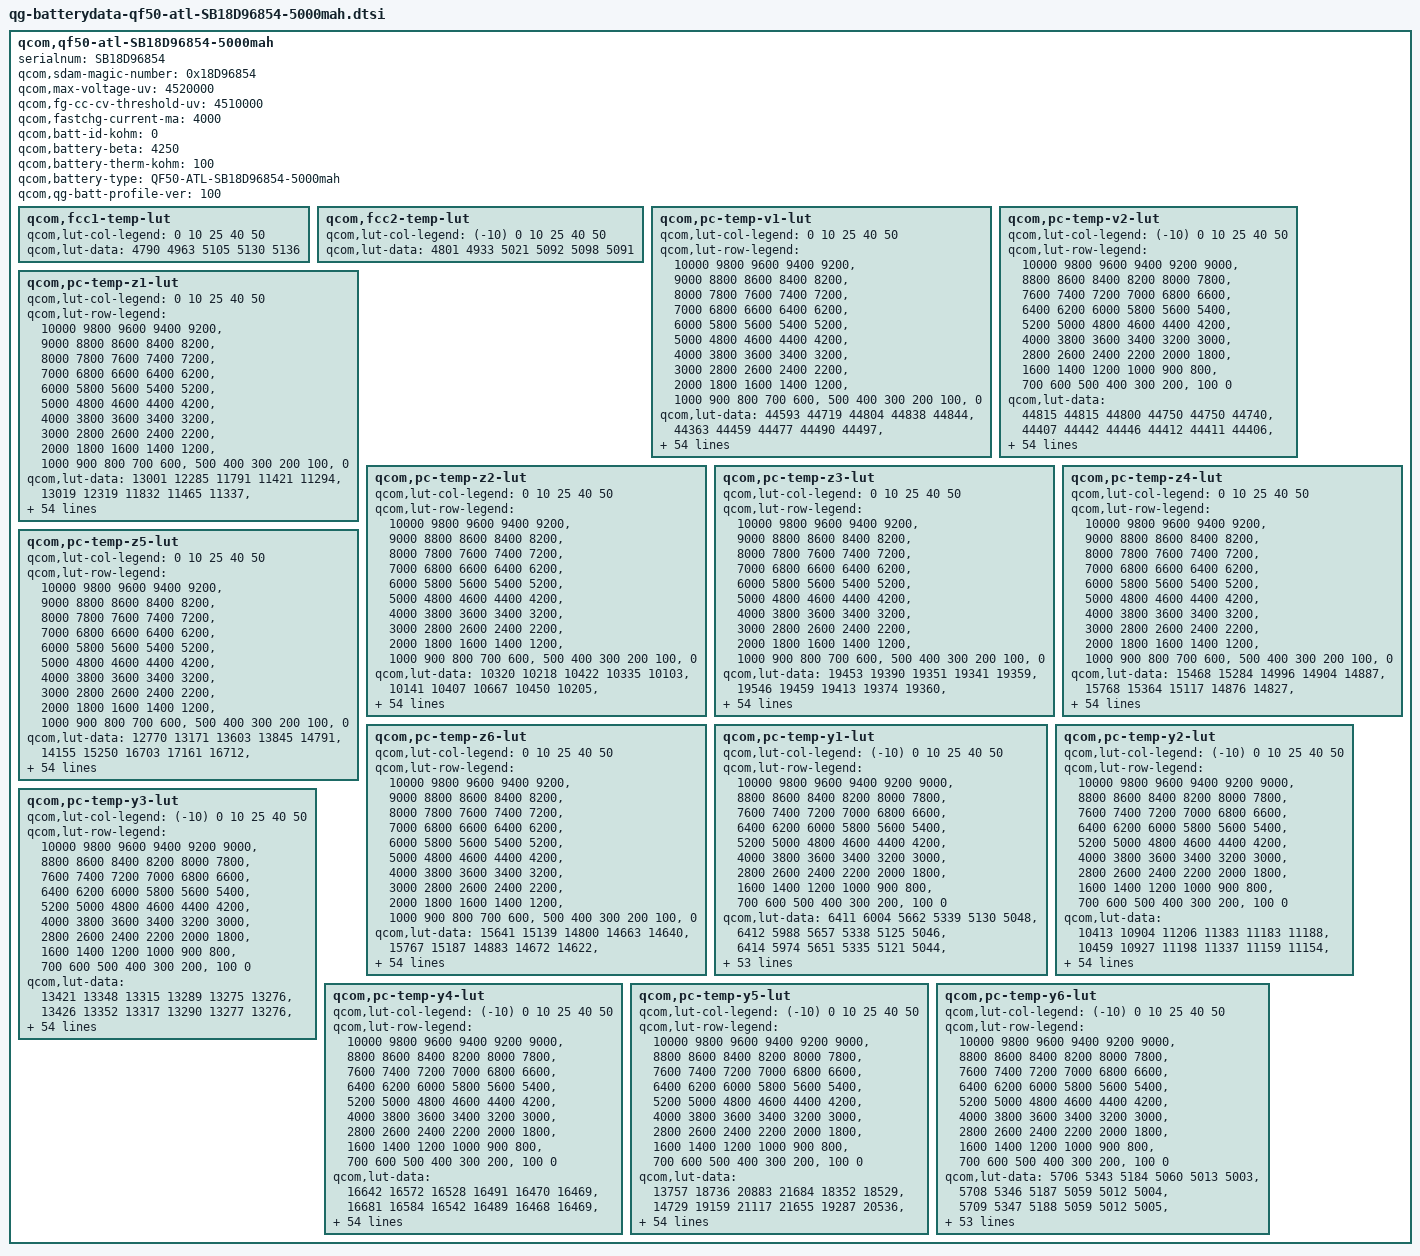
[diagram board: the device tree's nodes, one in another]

qcom,qf50-atl-SB18D96854-5000mah {
    /* ATL_SB18D96854_5000mAH_averaged_MasterSlave_Oct9th2023 */
    serialnum = "SB18D96854";
    qcom,sdam-magic-number = <0x18D96854>;
    qcom,max-voltage-uv = <4520000>;
    qcom,fg-cc-cv-threshold-uv = <4510000>;
    qcom,fastchg-current-ma = <4000>;
    qcom,batt-id-kohm = <0>;
    qcom,battery-beta = <4250>;
    qcom,battery-therm-kohm = <100>;
    qcom,battery-type = "QF50-ATL-SB18D96854-5000mah";
    qcom,qg-batt-profile-ver = <100>;

	qcom,fcc1-temp-lut {
		qcom,lut-col-legend = <0 10 25 40 50>;
		qcom,lut-data = <4790 4963 5105 5130 5136>;
	};

	qcom,fcc2-temp-lut {
		qcom,lut-col-legend = <(-10) 0 10 25 40 50>;
		qcom,lut-data = <4801 4933 5021 5092 5098 5091>;
	};

	qcom,pc-temp-v1-lut {
		qcom,lut-col-legend = <0 10 25 40 50>;
		qcom,lut-row-legend = <10000 9800 9600 9400 9200>,
			<9000 8800 8600 8400 8200>,
			<8000 7800 7600 7400 7200>,
			<7000 6800 6600 6400 6200>,
			<6000 5800 5600 5400 5200>,
			<5000 4800 4600 4400 4200>,
			<4000 3800 3600 3400 3200>,
			<3000 2800 2600 2400 2200>,
			<2000 1800 1600 1400 1200>,
			<1000 900 800 700 600>,
			<500 400 300 200 100>,
			<0>;
		qcom,lut-data = <44593 44719 44804 44838 44844>,
			<44363 44459 44477 44490 44497>,
			<44144 44230 44243 44243 44244>,
			<43927 44019 44035 44031 44030>,
			<43713 43810 43820 43818 43818>,
			<43498 43596 43604 43604 43606>,
			<43273 43372 43381 43385 43390>,
			<43035 43137 43142 43153 43158>,
			<42792 42894 42895 42911 42914>,
			<42551 42644 42646 42663 42666>,
			<42310 42393 42393 42408 42414>,
			<42073 42146 42141 42154 42162>,
			<41839 41903 41889 41903 41914>,
			<41609 41666 41642 41656 41669>,
			<41387 41435 41405 41418 41431>,
			<41171 41209 41175 41184 41198>,
			<40963 40990 40953 40960 40972>,
			<40761 40781 40738 40744 40753>,
			<40565 40581 40532 40539 40543>,
			<40376 40391 40342 40345 40348>,
			<40196 40208 40161 40165 40169>,
			<40017 40026 39958 39961 39968>,
			<39832 39829 39722 39704 39713>,
			<39642 39584 39487 39452 39461>,
			<39449 39308 39263 39253 39271>,
			<39236 39091 39056 39084 39112>,
			<39033 38952 38915 38947 38967>,
			<38893 38848 38817 38837 38830>,
			<38793 38757 38729 38737 38709>,
			<38708 38674 38639 38633 38609>,
			<38631 38593 38555 38534 38521>,
			<38562 38516 38475 38446 38438>,
			<38499 38443 38399 38368 38361>,
			<38440 38377 38330 38296 38287>,
			<38385 38316 38270 38227 38216>,
			<38335 38263 38215 38161 38145>,
			<38289 38219 38159 38095 38074>,
			<38243 38179 38104 38031 37999>,
			<38199 38129 38036 37954 37912>,
			<38151 38063 37943 37851 37796>,
			<38082 37978 37834 37733 37667>,
			<37977 37865 37713 37614 37543>,
			<37855 37731 37574 37487 37414>,
			<37710 37574 37403 37324 37244>,
			<37573 37406 37240 37171 37097>,
			<37402 37260 37123 37076 37019>,
			<37316 37197 37089 37042 36986>,
			<37241 37152 37063 37019 36962>,
			<37178 37120 37041 36998 36938>,
			<37126 37083 36997 36945 36882>,
			<37082 36997 36796 36700 36622>,
			<37038 36781 36363 36256 36180>,
			<36969 36458 35772 35667 35597>,
			<36769 35910 34953 34863 34801>,
			<36046 34963 33679 33606 33568>,
			<30000 30000 30000 30000 30000>;
	};

	qcom,pc-temp-v2-lut {
		qcom,lut-col-legend = <(-10) 0 10 25 40 50>;
		qcom,lut-row-legend = <10000 9800 9600 9400 9200 9000>,
			<8800 8600 8400 8200 8000 7800>,
			<7600 7400 7200 7000 6800 6600>,
			<6400 6200 6000 5800 5600 5400>,
			<5200 5000 4800 4600 4400 4200>,
			<4000 3800 3600 3400 3200 3000>,
			<2800 2600 2400 2200 2000 1800>,
			<1600 1400 1200 1000 900 800>,
			<700 600 500 400 300 200>,
			<100 0>;
		qcom,lut-data = <44815 44815 44800 44750 44750 44740>,
			<44407 44442 44446 44412 44411 44406>,
			<44058 44120 44138 44113 44111 44108>,
			<43782 43862 43887 43862 43858 43856>,
			<43570 43658 43684 43653 43646 43644>,
			<43370 43460 43482 43441 43432 43430>,
			<43150 43241 43259 43211 43203 43201>,
			<42924 43016 43028 42975 42968 42965>,
			<42694 42783 42789 42731 42725 42723>,
			<42460 42540 42539 42479 42474 42472>,
			<42225 42294 42288 42227 42223 42221>,
			<41992 42052 42042 41975 41972 41972>,
			<41761 41809 41797 41725 41722 41724>,
			<41530 41572 41555 41481 41480 41482>,
			<41301 41339 41316 41244 41245 41246>,
			<41073 41112 41084 41013 41016 41017>,
			<40839 40897 40859 40787 40791 40794>,
			<40599 40690 40642 40570 40575 40580>,
			<40356 40467 40440 40366 40372 40374>,
			<40111 40218 40252 40169 40175 40175>,
			<39864 39963 40042 39964 39983 39983>,
			<39631 39715 39777 39750 39796 39802>,
			<39413 39470 39500 39529 39597 39609>,
			<39208 39248 39262 39284 39341 39357>,
			<39016 39051 39053 39038 39072 39086>,
			<38835 38873 38871 38855 38882 38895>,
			<38669 38714 38718 38714 38743 38756>,
			<38518 38570 38583 38591 38623 38636>,
			<38381 38439 38460 38476 38512 38521>,
			<38272 38314 38347 38370 38411 38417>,
			<38185 38202 38244 38274 38318 38322>,
			<38109 38107 38149 38184 38232 38237>,
			<38038 38025 38060 38103 38153 38157>,
			<37972 37952 37977 38031 38083 38085>,
			<37909 37890 37898 37962 38015 38011>,
			<37847 37833 37832 37890 37930 37918>,
			<37785 37779 37777 37816 37833 37806>,
			<37721 37730 37725 37735 37733 37694>,
			<37655 37673 37667 37646 37630 37587>,
			<37584 37596 37598 37551 37525 37480>,
			<37506 37504 37511 37454 37428 37384>,
			<37421 37406 37402 37350 37328 37287>,
			<37330 37300 37266 37220 37200 37161>,
			<37233 37174 37106 37072 37060 37018>,
			<37130 37022 36934 36927 36933 36885>,
			<37023 36864 36784 36857 36879 36834>,
			<36972 36796 36726 36836 36868 36823>,
			<36922 36732 36672 36813 36853 36809>,
			<36865 36674 36610 36782 36827 36779>,
			<36798 36606 36517 36704 36751 36698>,
			<36719 36495 36306 36440 36464 36398>,
			<36622 36353 35951 35932 35962 35898>,
			<36513 36035 35540 35247 35298 35239>,
			<36210 35567 34813 34264 34365 34314>,
			<36001 35211 33926 32680 32928 32922>,
			<35909 34566 32099 29510 28715 29333>;
	};

	qcom,pc-temp-z1-lut {
		qcom,lut-col-legend = <0 10 25 40 50>;
		qcom,lut-row-legend = <10000 9800 9600 9400 9200>,
			<9000 8800 8600 8400 8200>,
			<8000 7800 7600 7400 7200>,
			<7000 6800 6600 6400 6200>,
			<6000 5800 5600 5400 5200>,
			<5000 4800 4600 4400 4200>,
			<4000 3800 3600 3400 3200>,
			<3000 2800 2600 2400 2200>,
			<2000 1800 1600 1400 1200>,
			<1000 900 800 700 600>,
			<500 400 300 200 100>,
			<0>;
		qcom,lut-data = <13001 12285 11791 11421 11294>,
			<13019 12319 11832 11465 11337>,
			<13012 12323 11823 11455 11331>,
			<13004 12312 11815 11449 11328>,
			<12989 12300 11804 11444 11325>,
			<12968 12290 11789 11438 11322>,
			<12954 12280 11775 11433 11319>,
			<12945 12265 11764 11427 11318>,
			<12938 12252 11753 11422 11316>,
			<12923 12239 11743 11419 11316>,
			<12886 12220 11733 11416 11315>,
			<12862 12197 11729 11415 11315>,
			<12835 12182 11729 11413 11314>,
			<12804 12175 11729 11411 11314>,
			<12788 12173 11728 11410 11313>,
			<12765 12171 11726 11411 11313>,
			<12751 12169 11724 11412 11313>,
			<12743 12166 11724 11412 11314>,
			<12730 12165 11723 11412 11316>,
			<12725 12164 11726 11413 11317>,
			<12725 12165 11731 11415 11318>,
			<12726 12172 11733 11416 11319>,
			<12727 12180 11736 11416 11319>,
			<12729 12183 11739 11417 11320>,
			<12733 12184 11742 11418 11321>,
			<12747 12186 11746 11421 11323>,
			<12765 12194 11751 11424 11325>,
			<12776 12207 11756 11429 11328>,
			<12783 12217 11761 11434 11331>,
			<12788 12225 11766 11437 11335>,
			<12792 12233 11771 11440 11338>,
			<12800 12240 11776 11444 11342>,
			<12807 12245 11782 11450 11346>,
			<12815 12245 11788 11455 11351>,
			<12823 12245 11794 11461 11354>,
			<12826 12247 11800 11467 11358>,
			<12825 12257 11808 11473 11362>,
			<12826 12269 11818 11478 11366>,
			<12837 12282 11829 11484 11371>,
			<12854 12304 11840 11490 11376>,
			<12872 12323 11850 11496 11381>,
			<12902 12333 11857 11503 11385>,
			<12916 12343 11863 11511 11389>,
			<12918 12366 11868 11517 11393>,
			<12935 12374 11882 11524 11398>,
			<12975 12375 11894 11529 11400>,
			<12971 12399 11900 11530 11400>,
			<12977 12377 11893 11530 11400>,
			<12956 12386 11897 11534 11404>,
			<12966 12372 11909 11537 11408>,
			<12970 12406 11912 11543 11411>,
			<12977 12402 11928 11550 11416>,
			<12964 12411 11935 11558 11424>,
			<12996 12424 11950 11570 11433>,
			<12996 12424 11950 11570 11433>,
			<12996 12424 11950 11570 11433>;
	};

	qcom,pc-temp-z2-lut {
		qcom,lut-col-legend = <0 10 25 40 50>;
		qcom,lut-row-legend = <10000 9800 9600 9400 9200>,
			<9000 8800 8600 8400 8200>,
			<8000 7800 7600 7400 7200>,
			<7000 6800 6600 6400 6200>,
			<6000 5800 5600 5400 5200>,
			<5000 4800 4600 4400 4200>,
			<4000 3800 3600 3400 3200>,
			<3000 2800 2600 2400 2200>,
			<2000 1800 1600 1400 1200>,
			<1000 900 800 700 600>,
			<500 400 300 200 100>,
			<0>;
		qcom,lut-data = <10320 10218 10422 10335 10103>,
			<10141 10407 10667 10450 10205>,
			<10292 10511 10675 10590 10322>,
			<10394 10562 10674 10605 10473>,
			<10383 10566 10664 10605 10528>,
			<10358 10535 10606 10557 10481>,
			<10340 10493 10544 10487 10415>,
			<10324 10459 10501 10412 10374>,
			<10310 10435 10463 10334 10340>,
			<10296 10417 10430 10317 10333>,
			<10281 10404 10399 10332 10338>,
			<10275 10400 10387 10344 10344>,
			<10276 10402 10400 10345 10332>,
			<10278 10409 10418 10346 10308>,
			<10281 10416 10425 10351 10289>,
			<10289 10425 10429 10366 10231>,
			<10300 10438 10435 10375 10192>,
			<10316 10454 10444 10330 10198>,
			<10338 10466 10454 10270 10210>,
			<10353 10474 10459 10268 10226>,
			<10364 10480 10463 10293 10255>,
			<10373 10486 10479 10340 10307>,
			<10381 10492 10570 10536 10519>,
			<10389 10513 10643 10715 10722>,
			<10399 10541 10589 10626 10658>,
			<10418 10548 10482 10388 10456>,
			<10438 10534 10455 10315 10437>,
			<10441 10521 10461 10337 10997>,
			<10434 10520 10471 10377 11471>,
			<10428 10522 10496 10506 11283>,
			<10430 10522 10529 10697 10847>,
			<10434 10521 10549 10723 10572>,
			<10438 10523 10564 10621 10384>,
			<10443 10530 10569 10506 10275>,
			<10448 10543 10561 10398 10227>,
			<10450 10550 10549 10310 10199>,
			<10451 10548 10547 10307 10209>,
			<10452 10542 10550 10339 10269>,
			<10454 10541 10555 10383 10335>,
			<10457 10549 10576 10475 10411>,
			<10460 10555 10601 10563 10475>,
			<10464 10550 10614 10570 10489>,
			<10468 10546 10625 10546 10489>,
			<10476 10543 10676 10539 10505>,
			<10258 10612 10693 10539 10500>,
			<10202 10680 10648 10509 10438>,
			<10111 10660 10634 10502 10437>,
			<10074 10647 10596 10512 10438>,
			<10038 10892 10565 10516 10442>,
			<9961 10981 10559 10578 10553>,
			<9920 10890 10626 10515 10467>,
			<9778 10816 10640 10340 10196>,
			<9713 10647 10580 10264 10119>,
			<9769 10508 10477 10193 10026>,
			<9769 10508 10477 10193 10026>,
			<9769 10508 10477 10193 10026>;
	};

	qcom,pc-temp-z3-lut {
		qcom,lut-col-legend = <0 10 25 40 50>;
		qcom,lut-row-legend = <10000 9800 9600 9400 9200>,
			<9000 8800 8600 8400 8200>,
			<8000 7800 7600 7400 7200>,
			<7000 6800 6600 6400 6200>,
			<6000 5800 5600 5400 5200>,
			<5000 4800 4600 4400 4200>,
			<4000 3800 3600 3400 3200>,
			<3000 2800 2600 2400 2200>,
			<2000 1800 1600 1400 1200>,
			<1000 900 800 700 600>,
			<500 400 300 200 100>,
			<0>;
		qcom,lut-data = <19453 19390 19351 19341 19359>,
			<19546 19459 19413 19374 19360>,
			<19608 19497 19429 19394 19385>,
			<19641 19516 19438 19401 19392>,
			<19650 19523 19443 19405 19395>,
			<19655 19526 19446 19409 19397>,
			<19658 19527 19449 19410 19399>,
			<19661 19526 19452 19411 19402>,
			<19662 19525 19454 19411 19406>,
			<19660 19524 19452 19411 19407>,
			<19654 19522 19444 19408 19403>,
			<19648 19518 19436 19404 19398>,
			<19643 19511 19433 19401 19393>,
			<19639 19503 19430 19397 19389>,
			<19633 19496 19424 19392 19384>,
			<19627 19492 19418 19387 19379>,
			<19621 19490 19413 19382 19374>,
			<19615 19489 19410 19377 19371>,
			<19608 19487 19408 19372 19367>,
			<19603 19484 19405 19367 19361>,
			<19598 19481 19401 19362 19354>,
			<19595 19479 19401 19361 19351>,
			<19596 19480 19412 19366 19355>,
			<19600 19488 19420 19373 19359>,
			<19605 19500 19415 19365 19351>,
			<19612 19504 19405 19345 19331>,
			<19618 19500 19399 19339 19329>,
			<19619 19494 19394 19339 19382>,
			<19615 19490 19392 19340 19427>,
			<19610 19487 19394 19355 19423>,
			<19606 19486 19396 19380 19410>,
			<19603 19487 19401 19387 19398>,
			<19600 19488 19409 19385 19388>,
			<19597 19489 19413 19382 19378>,
			<19594 19489 19412 19377 19367>,
			<19592 19489 19409 19369 19357>,
			<19591 19487 19407 19362 19348>,
			<19589 19484 19403 19354 19340>,
			<19586 19480 19400 19351 19337>,
			<19582 19477 19398 19352 19337>,
			<19577 19473 19396 19353 19338>,
			<19568 19468 19393 19352 19339>,
			<19559 19464 19388 19350 19344>,
			<19552 19461 19385 19351 19350>,
			<19343 19446 19379 19351 19352>,
			<19300 19427 19373 19340 19340>,
			<19299 19429 19370 19336 19336>,
			<19296 19423 19367 19332 19326>,
			<19297 19365 19359 19327 19321>,
			<19294 19359 19355 19322 19311>,
			<19292 19358 19350 19338 19329>,
			<19273 19320 19359 19359 19350>,
			<19275 19311 19353 19364 19351>,
			<19306 19391 19382 19359 19347>,
			<19306 19391 19382 19359 19347>,
			<19306 19391 19382 19359 19347>;
	};

	qcom,pc-temp-z4-lut {
		qcom,lut-col-legend = <0 10 25 40 50>;
		qcom,lut-row-legend = <10000 9800 9600 9400 9200>,
			<9000 8800 8600 8400 8200>,
			<8000 7800 7600 7400 7200>,
			<7000 6800 6600 6400 6200>,
			<6000 5800 5600 5400 5200>,
			<5000 4800 4600 4400 4200>,
			<4000 3800 3600 3400 3200>,
			<3000 2800 2600 2400 2200>,
			<2000 1800 1600 1400 1200>,
			<1000 900 800 700 600>,
			<500 400 300 200 100>,
			<0>;
		qcom,lut-data = <15468 15284 14996 14904 14887>,
			<15768 15364 15117 14876 14827>,
			<15625 15301 15092 14911 14870>,
			<15464 15176 15003 14874 14843>,
			<15334 15064 14942 14841 14818>,
			<15210 14985 14897 14816 14798>,
			<15114 14924 14858 14793 14779>,
			<15040 14876 14823 14773 14761>,
			<14980 14837 14792 14756 14743>,
			<14933 14805 14767 14741 14732>,
			<14894 14779 14746 14728 14725>,
			<14861 14758 14731 14719 14720>,
			<14833 14741 14721 14712 14716>,
			<14810 14730 14713 14707 14714>,
			<14790 14724 14707 14702 14710>,
			<14773 14719 14703 14697 14706>,
			<14760 14714 14698 14692 14703>,
			<14750 14710 14694 14688 14699>,
			<14742 14706 14690 14684 14696>,
			<14738 14703 14685 14679 14690>,
			<14736 14700 14681 14673 14683>,
			<14735 14699 14682 14672 14681>,
			<14736 14702 14703 14706 14715>,
			<14741 14726 14734 14754 14763>,
			<14749 14776 14778 14791 14795>,
			<14776 14807 14826 14824 14821>,
			<14809 14809 14834 14831 14822>,
			<14815 14801 14821 14819 14754>,
			<14811 14789 14804 14799 14695>,
			<14806 14773 14788 14769 14691>,
			<14800 14761 14770 14731 14689>,
			<14792 14751 14754 14709 14687>,
			<14785 14742 14737 14697 14683>,
			<14779 14738 14724 14688 14679>,
			<14774 14735 14714 14683 14675>,
			<14769 14733 14708 14679 14671>,
			<14764 14730 14704 14677 14669>,
			<14758 14727 14702 14675 14668>,
			<14747 14721 14701 14675 14668>,
			<14733 14714 14703 14684 14681>,
			<14722 14706 14705 14694 14697>,
			<14714 14698 14702 14692 14693>,
			<14702 14688 14694 14686 14682>,
			<14685 14674 14688 14687 14686>,
			<14845 14654 14674 14681 14682>,
			<14881 14650 14656 14663 14658>,
			<14886 14648 14651 14661 14655>,
			<14889 14651 14641 14649 14650>,
			<14890 14712 14636 14633 14632>,
			<14892 14711 14633 14625 14623>,
			<14896 14712 14653 14644 14652>,
			<14913 14758 14660 14646 14659>,
			<14913 14772 14671 14649 14666>,
			<14897 14700 14650 14658 14676>,
			<14897 14700 14650 14658 14676>,
			<14897 14700 14650 14658 14676>;
	};

	qcom,pc-temp-z5-lut {
		qcom,lut-col-legend = <0 10 25 40 50>;
		qcom,lut-row-legend = <10000 9800 9600 9400 9200>,
			<9000 8800 8600 8400 8200>,
			<8000 7800 7600 7400 7200>,
			<7000 6800 6600 6400 6200>,
			<6000 5800 5600 5400 5200>,
			<5000 4800 4600 4400 4200>,
			<4000 3800 3600 3400 3200>,
			<3000 2800 2600 2400 2200>,
			<2000 1800 1600 1400 1200>,
			<1000 900 800 700 600>,
			<500 400 300 200 100>,
			<0>;
		qcom,lut-data = <12770 13171 13603 13845 14791>,
			<14155 15250 16703 17161 16712>,
			<15460 16798 17519 18575 19208>,
			<16507 17913 18278 19681 20781>,
			<17186 18716 18887 20445 21736>,
			<17735 19366 19336 20933 22218>,
			<18429 19987 19885 21377 22705>,
			<19387 20692 20888 21887 23950>,
			<20341 21617 22034 22444 26078>,
			<21051 22826 22766 23242 27486>,
			<21655 24169 23290 24520 28328>,
			<22383 25267 23936 25735 28849>,
			<23447 25874 25182 26603 29118>,
			<24676 26278 26306 27346 29297>,
			<25805 26748 26600 28103 29405>,
			<26879 27468 26723 29040 29718>,
			<28024 28540 26995 29658 30204>,
			<29464 29831 27992 29953 31496>,
			<31008 30970 29250 30340 33168>,
			<32018 31779 30130 30977 34135>,
			<32501 32440 30986 32230 35013>,
			<33039 33461 33285 34023 35569>,
			<34762 35326 42233 37909 36591>,
			<38685 41967 48954 41144 37496>,
			<42761 50144 43988 36443 33101>,
			<47271 51347 33537 24211 21515>,
			<51182 45323 28145 19084 18742>,
			<51272 38177 25092 17811 31918>,
			<47274 35211 23837 17285 43132>,
			<43386 33897 23940 19345 41578>,
			<41870 33680 24227 23800 37626>,
			<40821 34980 25322 26459 35269>,
			<40346 37363 28909 28337 33930>,
			<40332 39788 32294 29801 32727>,
			<40471 42627 34928 31077 31246>,
			<40676 44423 36976 32038 30007>,
			<41267 44306 37918 32266 29648>,
			<41819 43290 38596 32320 29483>,
			<42486 42860 38766 32466 29448>,
			<43208 42704 38184 33667 30081>,
			<43053 42357 37154 34906 30791>,
			<41032 40933 34830 32644 30390>,
			<39874 40008 31931 27841 29417>,
			<39457 41456 32112 28117 32563>,
			<16752 43769 33346 29173 35034>,
			<12168 37632 34020 25175 27594>,
			<12050 37832 31527 23178 24373>,
			<11976 32847 31875 22986 21175>,
			<11899 21596 27076 24858 24152>,
			<11793 20594 26452 25614 23689>,
			<11695 20551 21808 28233 27428>,
			<11387 13263 21748 28593 25239>,
			<11376 12965 18254 26587 21405>,
			<12509 24364 25760 20450 17080>,
			<12509 24364 25760 20450 17080>,
			<12509 24364 25760 20450 17080>;
	};

	qcom,pc-temp-z6-lut {
		qcom,lut-col-legend = <0 10 25 40 50>;
		qcom,lut-row-legend = <10000 9800 9600 9400 9200>,
			<9000 8800 8600 8400 8200>,
			<8000 7800 7600 7400 7200>,
			<7000 6800 6600 6400 6200>,
			<6000 5800 5600 5400 5200>,
			<5000 4800 4600 4400 4200>,
			<4000 3800 3600 3400 3200>,
			<3000 2800 2600 2400 2200>,
			<2000 1800 1600 1400 1200>,
			<1000 900 800 700 600>,
			<500 400 300 200 100>,
			<0>;
		qcom,lut-data = <15641 15139 14800 14663 14640>,
			<15767 15187 14883 14672 14622>,
			<15698 15163 14873 14694 14650>,
			<15615 15108 14835 14682 14643>,
			<15538 15052 14808 14671 14635>,
			<15459 15006 14786 14660 14628>,
			<15394 14969 14766 14651 14620>,
			<15341 14939 14749 14642 14614>,
			<15296 14912 14734 14634 14609>,
			<15255 14890 14718 14626 14604>,
			<15218 14870 14702 14619 14599>,
			<15186 14852 14691 14612 14594>,
			<15159 14836 14684 14607 14590>,
			<15135 14824 14678 14602 14586>,
			<15113 14817 14672 14597 14581>,
			<15093 14812 14666 14592 14576>,
			<15077 14808 14662 14587 14572>,
			<15065 14805 14658 14582 14568>,
			<15056 14802 14655 14577 14564>,
			<15052 14800 14652 14572 14559>,
			<15050 14798 14649 14567 14552>,
			<15049 14798 14650 14566 14550>,
			<15050 14800 14664 14586 14568>,
			<15058 14817 14682 14609 14591>,
			<15067 14846 14700 14618 14596>,
			<15086 14862 14716 14624 14599>,
			<15106 14863 14718 14624 14599>,
			<15109 14859 14711 14619 14599>,
			<15107 14853 14703 14613 14599>,
			<15104 14848 14698 14610 14595>,
			<15102 14844 14693 14607 14588>,
			<15100 14842 14690 14602 14582>,
			<15099 14841 14688 14597 14576>,
			<15098 14841 14686 14592 14569>,
			<15096 14842 14683 14587 14562>,
			<15096 14843 14681 14583 14556>,
			<15096 14844 14680 14579 14550>,
			<15097 14844 14679 14575 14546>,
			<15099 14844 14679 14573 14544>,
			<15101 14846 14682 14578 14550>,
			<15105 14847 14684 14584 14557>,
			<15109 14848 14683 14583 14558>,
			<15114 14848 14681 14581 14557>,
			<15119 14849 14681 14583 14561>,
			<15107 14847 14678 14581 14561>,
			<15109 14842 14669 14569 14545>,
			<15112 14845 14666 14566 14542>,
			<15115 14843 14660 14559 14535>,
			<15117 14842 14655 14550 14524>,
			<15119 14842 14655 14545 14516>,
			<15121 14847 14665 14563 14538>,
			<15125 14853 14677 14577 14555>,
			<15137 14864 14684 14583 14561>,
			<15160 14886 14698 14588 14566>,
			<15160 14886 14698 14588 14566>,
			<15160 14886 14698 14588 14566>;
	};

	qcom,pc-temp-y1-lut {
		qcom,lut-col-legend = <(-10) 0 10 25 40 50>;
		qcom,lut-row-legend = <10000 9800 9600 9400 9200 9000>,
			<8800 8600 8400 8200 8000 7800>,
			<7600 7400 7200 7000 6800 6600>,
			<6400 6200 6000 5800 5600 5400>,
			<5200 5000 4800 4600 4400 4200>,
			<4000 3800 3600 3400 3200 3000>,
			<2800 2600 2400 2200 2000 1800>,
			<1600 1400 1200 1000 900 800>,
			<700 600 500 400 300 200>,
			<100 0>;
		qcom,lut-data = <6411 6004 5662 5339 5130 5048>,
			<6412 5988 5657 5338 5125 5046>,
			<6414 5974 5651 5335 5121 5044>,
			<6415 5963 5645 5331 5117 5043>,
			<6418 5956 5641 5327 5113 5041>,
			<6421 5953 5637 5324 5110 5039>,
			<6427 5957 5635 5320 5106 5036>,
			<6434 5965 5634 5315 5103 5034>,
			<6436 5967 5630 5311 5100 5033>,
			<6422 5965 5622 5306 5097 5033>,
			<6405 5963 5614 5302 5095 5032>,
			<6404 5960 5605 5299 5093 5030>,
			<6414 5955 5597 5296 5091 5028>,
			<6425 5954 5595 5295 5090 5027>,
			<6438 5957 5598 5295 5089 5027>,
			<6454 5959 5600 5295 5088 5027>,
			<6458 5956 5596 5294 5087 5026>,
			<6453 5948 5589 5292 5087 5027>,
			<6446 5946 5587 5292 5088 5027>,
			<6443 5950 5590 5294 5089 5029>,
			<6446 5957 5594 5295 5090 5030>,
			<6447 5968 5601 5296 5090 5030>,
			<6436 5985 5605 5298 5091 5031>,
			<6423 5992 5606 5302 5093 5032>,
			<6423 5984 5607 5307 5096 5034>,
			<6429 5974 5610 5311 5098 5036>,
			<6435 5972 5614 5314 5101 5037>,
			<6440 5966 5618 5318 5103 5039>,
			<6444 5964 5619 5322 5106 5041>,
			<6444 5968 5618 5326 5108 5043>,
			<6434 5973 5618 5330 5111 5045>,
			<6424 5982 5621 5334 5115 5047>,
			<6431 5998 5628 5337 5118 5050>,
			<6451 6006 5636 5339 5122 5052>,
			<6460 5995 5642 5342 5125 5054>,
			<6453 5981 5642 5345 5128 5056>,
			<6443 5981 5644 5349 5132 5059>,
			<6441 5990 5645 5353 5134 5061>,
			<6444 5996 5644 5357 5136 5063>,
			<6446 5987 5642 5362 5137 5064>,
			<6445 5973 5643 5366 5139 5065>,
			<6442 5971 5649 5371 5141 5066>,
			<6438 5977 5661 5376 5142 5068>,
			<6428 5979 5665 5382 5145 5070>,
			<6428 5978 5658 5393 5148 5073>,
			<6456 5991 5678 5395 5154 5077>,
			<6456 6006 5663 5405 5159 5078>,
			<6453 6000 5670 5411 5156 5079>,
			<6489 6040 5677 5410 5154 5079>,
			<6581 6103 5732 5416 5156 5078>,
			<6667 6171 5786 5421 5157 5079>,
			<6720 6292 5877 5433 5161 5082>,
			<6860 6626 6181 5467 5168 5087>,
			<7049 6682 6246 5485 5177 5095>,
			<7049 6682 6246 5485 5177 5095>,
			<7049 6682 6246 5485 5177 5095>;
	};

	qcom,pc-temp-y2-lut {
		qcom,lut-col-legend = <(-10) 0 10 25 40 50>;
		qcom,lut-row-legend = <10000 9800 9600 9400 9200 9000>,
			<8800 8600 8400 8200 8000 7800>,
			<7600 7400 7200 7000 6800 6600>,
			<6400 6200 6000 5800 5600 5400>,
			<5200 5000 4800 4600 4400 4200>,
			<4000 3800 3600 3400 3200 3000>,
			<2800 2600 2400 2200 2000 1800>,
			<1600 1400 1200 1000 900 800>,
			<700 600 500 400 300 200>,
			<100 0>;
		qcom,lut-data = <10413 10904 11206 11383 11183 11188>,
			<10459 10927 11198 11337 11159 11154>,
			<10522 10942 11186 11289 11121 11115>,
			<10588 10951 11170 11243 11078 11073>,
			<10645 10955 11151 11201 11034 11027>,
			<10680 10957 11130 11167 10996 10979>,
			<10691 10952 11103 11135 10946 10918>,
			<10697 10940 11075 11109 10898 10864>,
			<10705 10929 11053 11092 10883 10839>,
			<10716 10916 11026 11078 10876 10825>,
			<10730 10907 11011 11070 10870 10810>,
			<10745 10910 11013 11072 10868 10787>,
			<10760 10919 11020 11076 10867 10768>,
			<10778 10931 11028 11079 10860 10764>,
			<10806 10952 11042 11088 10842 10766>,
			<10839 10980 11061 11102 10845 10774>,
			<10866 11018 11090 11138 10900 10814>,
			<10892 11063 11131 11184 10971 10856>,
			<10908 11089 11186 11236 11015 10869>,
			<10910 11101 11258 11299 11057 10874>,
			<10909 11109 11292 11326 11142 10921>,
			<10906 11111 11269 11338 11359 11188>,
			<10894 11111 11236 11345 11503 11392>,
			<10875 11113 11238 11318 11384 11305>,
			<10856 11123 11261 11267 11171 11138>,
			<10837 11134 11271 11262 11108 11091>,
			<10804 11134 11265 11302 11096 11095>,
			<10480 11126 11263 11341 11100 11111>,
			<9951 11119 11280 11360 11149 11166>,
			<9769 11114 11300 11375 11223 11241>,
			<9738 11105 11304 11395 11263 11274>,
			<9721 11092 11305 11420 11289 11288>,
			<9711 11066 11304 11442 11328 11308>,
			<9704 11036 11300 11468 11452 11376>,
			<9697 10997 11279 11487 11573 11446>,
			<9691 10949 11247 11485 11565 11425>,
			<9685 10902 11216 11468 11499 11319>,
			<9680 10855 11183 11447 11435 11248>,
			<9676 10779 11133 11417 11360 11218>,
			<9673 10435 11056 11379 11296 11201>,
			<9671 9952 10968 11331 11258 11214>,
			<9669 9778 10877 11280 11225 11241>,
			<9667 9718 10669 11270 11246 11227>,
			<9664 9692 10363 11248 11239 11165>,
			<9662 9679 10064 11121 11159 11025>,
			<9659 9668 9852 11102 11024 10843>,
			<9658 9664 9800 11046 11049 10828>,
			<9655 9660 9728 11073 11095 10849>,
			<9652 9655 9685 11126 11085 10848>,
			<9650 9650 9667 11121 11054 10868>,
			<9648 9648 9657 10968 11005 10765>,
			<9648 9648 9651 10746 10871 10731>,
			<9647 9648 9649 10517 10798 10647>,
			<9647 9648 9649 9961 10671 10492>,
			<9647 9648 9649 9961 10671 10492>,
			<9647 9648 9649 9961 10671 10492>;
	};

	qcom,pc-temp-y3-lut {
		qcom,lut-col-legend = <(-10) 0 10 25 40 50>;
		qcom,lut-row-legend = <10000 9800 9600 9400 9200 9000>,
			<8800 8600 8400 8200 8000 7800>,
			<7600 7400 7200 7000 6800 6600>,
			<6400 6200 6000 5800 5600 5400>,
			<5200 5000 4800 4600 4400 4200>,
			<4000 3800 3600 3400 3200 3000>,
			<2800 2600 2400 2200 2000 1800>,
			<1600 1400 1200 1000 900 800>,
			<700 600 500 400 300 200>,
			<100 0>;
		qcom,lut-data = <13421 13348 13315 13289 13275 13276>,
			<13426 13352 13317 13290 13277 13276>,
			<13433 13355 13319 13291 13278 13277>,
			<13440 13359 13322 13292 13279 13278>,
			<13446 13362 13323 13293 13280 13279>,
			<13449 13365 13325 13294 13281 13280>,
			<13449 13366 13326 13295 13282 13281>,
			<13448 13368 13326 13296 13283 13281>,
			<13447 13368 13327 13297 13284 13282>,
			<13445 13368 13326 13298 13285 13282>,
			<13444 13368 13326 13298 13285 13283>,
			<13442 13368 13328 13298 13286 13283>,
			<13441 13367 13329 13299 13286 13284>,
			<13439 13366 13329 13299 13287 13285>,
			<13436 13364 13329 13301 13289 13286>,
			<13433 13363 13328 13302 13291 13287>,
			<13429 13363 13327 13302 13291 13289>,
			<13424 13363 13325 13301 13292 13290>,
			<13418 13362 13325 13300 13293 13290>,
			<13412 13359 13326 13298 13295 13290>,
			<13406 13354 13326 13297 13295 13290>,
			<13400 13349 13322 13297 13293 13290>,
			<13395 13344 13317 13297 13291 13290>,
			<13390 13340 13313 13295 13286 13286>,
			<13386 13338 13311 13292 13280 13278>,
			<13381 13335 13309 13290 13279 13276>,
			<13376 13333 13308 13290 13278 13277>,
			<13369 13330 13307 13290 13278 13278>,
			<13361 13328 13306 13289 13279 13277>,
			<13360 13326 13306 13289 13279 13276>,
			<13363 13323 13305 13289 13279 13276>,
			<13368 13322 13305 13289 13278 13276>,
			<13376 13321 13305 13289 13278 13276>,
			<13390 13321 13304 13289 13279 13277>,
			<13406 13322 13303 13289 13281 13278>,
			<13422 13323 13303 13289 13281 13278>,
			<13442 13326 13304 13288 13280 13278>,
			<13466 13332 13306 13288 13280 13278>,
			<13496 13339 13308 13287 13280 13278>,
			<13533 13343 13309 13287 13280 13279>,
			<13578 13348 13312 13287 13280 13280>,
			<13634 13359 13314 13287 13280 13281>,
			<13703 13385 13316 13288 13280 13280>,
			<13792 13419 13319 13288 13279 13279>,
			<13916 13467 13324 13287 13277 13277>,
			<14114 13582 13347 13291 13283 13282>,
			<14299 13671 13378 13293 13286 13285>,
			<14686 13865 13456 13296 13289 13288>,
			<15312 14418 13757 13303 13292 13288>,
			<16728 16496 15323 13308 13291 13288>,
			<20371 23244 21973 13307 13287 13285>,
			<29778 47788 47032 13309 13287 13284>,
			<58541 65535 65535 13324 13290 13287>,
			<65535 65535 65535 13369 13296 13294>,
			<65535 65535 65535 13369 13296 13294>,
			<65535 65535 65535 13369 13296 13294>;
	};

	qcom,pc-temp-y4-lut {
		qcom,lut-col-legend = <(-10) 0 10 25 40 50>;
		qcom,lut-row-legend = <10000 9800 9600 9400 9200 9000>,
			<8800 8600 8400 8200 8000 7800>,
			<7600 7400 7200 7000 6800 6600>,
			<6400 6200 6000 5800 5600 5400>,
			<5200 5000 4800 4600 4400 4200>,
			<4000 3800 3600 3400 3200 3000>,
			<2800 2600 2400 2200 2000 1800>,
			<1600 1400 1200 1000 900 800>,
			<700 600 500 400 300 200>,
			<100 0>;
		qcom,lut-data = <16642 16572 16528 16491 16470 16469>,
			<16681 16584 16542 16489 16468 16469>,
			<16731 16611 16558 16488 16466 16469>,
			<16784 16643 16573 16487 16464 16469>,
			<16829 16670 16584 16486 16463 16469>,
			<16857 16683 16588 16486 16462 16469>,
			<16869 16683 16586 16485 16463 16468>,
			<16876 16683 16582 16485 16463 16467>,
			<16878 16682 16577 16485 16464 16467>,
			<16877 16677 16571 16487 16465 16466>,
			<16876 16674 16568 16488 16466 16466>,
			<16878 16676 16569 16492 16469 16467>,
			<16884 16681 16570 16498 16473 16470>,
			<16889 16690 16574 16504 16476 16472>,
			<16891 16704 16584 16511 16479 16474>,
			<16893 16722 16599 16520 16483 16477>,
			<16892 16741 16618 16532 16489 16480>,
			<16876 16761 16642 16548 16496 16483>,
			<16852 16766 16669 16574 16505 16489>,
			<16824 16746 16698 16606 16516 16499>,
			<16786 16714 16708 16614 16533 16514>,
			<16750 16678 16669 16609 16565 16543>,
			<16718 16635 16606 16600 16584 16562>,
			<16688 16601 16560 16557 16545 16533>,
			<16657 16576 16526 16489 16478 16478>,
			<16622 16557 16507 16472 16463 16463>,
			<16605 16545 16501 16469 16462 16461>,
			<16616 16537 16497 16469 16462 16460>,
			<16637 16529 16495 16472 16466 16463>,
			<16651 16519 16495 16478 16474 16470>,
			<16659 16510 16494 16484 16482 16478>,
			<16664 16509 16494 16491 16493 16487>,
			<16663 16509 16492 16498 16502 16497>,
			<16661 16510 16490 16508 16511 16508>,
			<16660 16515 16487 16516 16518 16516>,
			<16663 16524 16488 16516 16515 16514>,
			<16668 16531 16494 16512 16505 16501>,
			<16672 16538 16506 16506 16494 16490>,
			<16677 16547 16518 16493 16482 16483>,
			<16680 16565 16527 16482 16473 16479>,
			<16683 16587 16529 16483 16475 16483>,
			<16685 16596 16527 16487 16481 16492>,
			<16686 16600 16526 16487 16477 16488>,
			<16686 16602 16527 16484 16464 16470>,
			<16686 16603 16528 16468 16444 16441>,
			<16688 16603 16542 16478 16456 16460>,
			<16692 16596 16549 16493 16478 16494>,
			<16715 16600 16568 16514 16514 16534>,
			<16767 16619 16600 16544 16554 16571>,
			<16936 16842 16865 16578 16569 16579>,
			<17379 17864 19413 16557 16500 16501>,
			<18670 22588 32944 16542 16475 16481>,
			<20729 38525 58970 16572 16478 16478>,
			<18799 21886 65535 16656 16484 16478>,
			<18799 21886 65535 16656 16484 16478>,
			<18799 21886 65535 16656 16484 16478>;
	};

	qcom,pc-temp-y5-lut {
		qcom,lut-col-legend = <(-10) 0 10 25 40 50>;
		qcom,lut-row-legend = <10000 9800 9600 9400 9200 9000>,
			<8800 8600 8400 8200 8000 7800>,
			<7600 7400 7200 7000 6800 6600>,
			<6400 6200 6000 5800 5600 5400>,
			<5200 5000 4800 4600 4400 4200>,
			<4000 3800 3600 3400 3200 3000>,
			<2800 2600 2400 2200 2000 1800>,
			<1600 1400 1200 1000 900 800>,
			<700 600 500 400 300 200>,
			<100 0>;
		qcom,lut-data = <13757 18736 20883 21684 18352 18529>,
			<14729 19159 21117 21655 19287 20536>,
			<15961 19662 21390 21504 19911 21857>,
			<17234 20160 21650 21300 20282 22633>,
			<18329 20572 21844 21107 20460 23007>,
			<19028 20812 21921 20988 20499 23117>,
			<19309 20914 21744 20564 20294 22669>,
			<19486 20961 21405 20013 19936 21952>,
			<19575 20882 20971 19734 19596 21386>,
			<19596 20483 20158 19258 19116 20358>,
			<19615 19976 19559 18704 18525 19482>,
			<19688 19447 19329 17877 17531 18791>,
			<19808 18884 19152 17109 16744 18283>,
			<19964 18601 18698 16819 16840 18052>,
			<20262 18443 17804 16654 17221 17880>,
			<20713 18358 17294 16416 17324 17835>,
			<21199 18893 17057 15817 16848 17958>,
			<21832 20362 16893 15291 16323 17990>,
			<22339 21539 17467 15177 16111 17282>,
			<22548 22435 19689 15170 15968 15983>,
			<22705 23105 21706 15720 16078 15721>,
			<22797 23458 23028 19588 17331 16849>,
			<22923 23730 23912 23098 18822 18156>,
			<23042 23810 24151 24117 20088 19098>,
			<22959 23655 24201 24740 21162 19894>,
			<22380 23396 24203 24794 21160 20116>,
			<21448 23097 24104 24428 20138 20148>,
			<18495 22626 24137 23962 19268 20082>,
			<14313 22108 24331 23314 18857 18801>,
			<12904 21395 24558 22670 18496 16867>,
			<12629 20533 24860 22565 18073 16338>,
			<12504 19649 25447 22720 17553 16176>,
			<12598 18647 26036 22954 17378 16134>,
			<12893 18049 25347 23449 18919 16934>,
			<13139 17876 23594 24122 21060 18278>,
			<13291 17943 22691 24730 22051 19313>,
			<13423 18647 22992 25392 22713 20260>,
			<13565 20667 23751 25582 22899 20913>,
			<13724 21892 24266 24620 22721 21415>,
			<13805 19681 24201 23297 22419 21881>,
			<13784 16149 23797 22364 21959 22304>,
			<13740 15231 23427 21652 21450 22842>,
			<13697 15136 22050 21663 21820 24702>,
			<13537 14795 19185 21708 22133 25788>,
			<13440 13998 16405 21153 20560 20743>,
			<13224 13615 14656 20845 19115 18435>,
			<13102 13785 14840 19534 19128 17025>,
			<12819 13673 14566 19149 17959 16298>,
			<12154 13255 13985 19715 17292 15466>,
			<10896 11319 12609 19704 16706 15146>,
			<10069 9739 11643 19628 17368 15969>,
			<9495 9288 11433 19139 17680 15674>,
			<10113 9100 9645 18866 17639 15735>,
			<24779 16968 8914 15747 19845 17666>,
			<24779 16968 8914 15747 19845 17666>,
			<24779 16968 8914 15747 19845 17666>;
	};

	qcom,pc-temp-y6-lut {
		qcom,lut-col-legend = <(-10) 0 10 25 40 50>;
		qcom,lut-row-legend = <10000 9800 9600 9400 9200 9000>,
			<8800 8600 8400 8200 8000 7800>,
			<7600 7400 7200 7000 6800 6600>,
			<6400 6200 6000 5800 5600 5400>,
			<5200 5000 4800 4600 4400 4200>,
			<4000 3800 3600 3400 3200 3000>,
			<2800 2600 2400 2200 2000 1800>,
			<1600 1400 1200 1000 900 800>,
			<700 600 500 400 300 200>,
			<100 0>;
		qcom,lut-data = <5706 5343 5184 5060 5013 5003>,
			<5708 5346 5187 5059 5012 5004>,
			<5709 5347 5188 5059 5012 5005>,
			<5709 5348 5188 5058 5012 5005>,
			<5709 5349 5187 5057 5012 5006>,
			<5708 5349 5185 5057 5013 5006>,
			<5705 5347 5182 5056 5013 5007>,
			<5700 5342 5178 5056 5014 5007>,
			<5695 5337 5174 5056 5014 5007>,
			<5688 5332 5168 5056 5015 5007>,
			<5682 5328 5165 5056 5015 5007>,
			<5678 5325 5163 5057 5016 5008>,
			<5675 5324 5162 5058 5017 5009>,
			<5672 5323 5162 5060 5019 5010>,
			<5670 5324 5163 5063 5021 5012>,
			<5667 5326 5165 5066 5023 5013>,
			<5663 5329 5168 5069 5025 5015>,
			<5657 5334 5173 5073 5028 5017>,
			<5649 5336 5180 5079 5031 5019>,
			<5639 5328 5188 5087 5036 5022>,
			<5627 5315 5192 5089 5041 5026>,
			<5617 5303 5178 5088 5048 5034>,
			<5609 5289 5157 5085 5052 5040>,
			<5602 5279 5142 5071 5038 5028>,
			<5597 5272 5131 5050 5014 5006>,
			<5593 5268 5126 5045 5009 5001>,
			<5591 5267 5125 5045 5009 5001>,
			<5593 5266 5124 5045 5008 5001>,
			<5598 5266 5125 5046 5010 5002>,
			<5604 5267 5126 5048 5013 5004>,
			<5617 5269 5128 5051 5015 5006>,
			<5634 5273 5129 5053 5018 5008>,
			<5652 5280 5131 5057 5021 5011>,
			<5673 5288 5133 5061 5025 5016>,
			<5697 5300 5135 5064 5029 5019>,
			<5724 5314 5139 5065 5028 5018>,
			<5755 5332 5146 5064 5025 5014>,
			<5788 5354 5156 5064 5022 5012>,
			<5825 5378 5167 5061 5018 5010>,
			<5866 5404 5179 5059 5016 5009>,
			<5914 5433 5193 5060 5017 5011>,
			<5971 5469 5208 5063 5019 5015>,
			<6038 5516 5228 5066 5018 5014>,
			<6122 5575 5255 5068 5014 5008>,
			<6240 5655 5291 5065 5008 4999>,
			<6430 5795 5363 5075 5016 5009>,
			<6606 5891 5425 5083 5026 5021>,
			<6972 6085 5544 5095 5038 5034>,
			<7544 6596 5860 5111 5051 5046>,
			<8747 8345 7200 5128 5055 5048>,
			<11606 13494 12686 5126 5033 5023>,
			<18572 31573 33627 5137 5026 5018>,
			<38708 65535 65535 5192 5030 5021>,
			<65535 65535 65535 5334 5038 5026>,
			<65535 65535 65535 5334 5038 5026>,
			<65535 65535 65535 5334 5038 5026>;
	};

};
